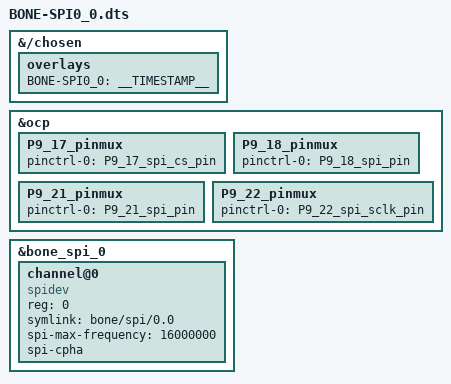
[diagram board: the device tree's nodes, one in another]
/*
 * Copyright (C) 2020 Deepak Khatri <deepaklorkhatri7@gmail.com>
 *
 * Virtual cape for /dev/bone/spi/0.0
 *
 * This program is free software; you can redistribute it and/or modify
 * it under the terms of the GNU General Public License version 2 as
 * published by the Free Software Foundation.
 */

/dts-v1/;
/plugin/;

/*
* Helper to show loaded overlays under: /proc/device-tree/chosen/overlays/
*/
&{/chosen} {
    overlays {
        BONE-SPI0_0 = __TIMESTAMP__;
    };
};

/*
 * Update the default pinmux of the pins.
 * See these files for the phandles (&P9_* & &P8_*)
 * https://github.com/lorforlinux/BeagleBoard-DeviceTrees/blob/compatibility/src/arm/am335x-bone-common-univ.dtsi
 * https://github.com/lorforlinux/BeagleBoard-DeviceTrees/blob/compatibility/src/arm/am572x-bone-common-univ.dtsi
 */
&ocp {
    P9_17_pinmux { pinctrl-0 = <&P9_17_spi_cs_pin>; }; /* CS*/
    P9_18_pinmux { pinctrl-0 = <&P9_18_spi_pin>; }; /* MOSI */
    P9_21_pinmux { pinctrl-0 = <&P9_21_spi_pin>; }; /* MISO */
    P9_22_pinmux { pinctrl-0 = <&P9_22_spi_sclk_pin>; }; /* CLK */
};

/*
 * See these files for the phandles (&bone_*) and other bone bus nodes
 * https://github.com/lorforlinux/BeagleBoard-DeviceTrees/blob/compatibility/src/arm/bbai-bone-buses.dtsi
 * https://github.com/lorforlinux/BeagleBoard-DeviceTrees/blob/compatibility/src/arm/bbb-bone-buses.dtsi
 */
&bone_spi_0 {
	status = "okay";
    #address-cells = <1>;
    #size-cells = <0>;

	channel@0 {
		reg = <0>;
		compatible = "spidev";
		symlink = "bone/spi/0.0";
		spi-max-frequency = <16000000>;
        spi-cpha;
	};
};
